# MEC1322 register map
Vendor: Microchip Technology Inc.; Series: ARMCM4F; File version: 1.0
CPU: CM4 r1p0, little endian, MPU, FPU, 3 interrupt priority bits
Registers are 32-bit, read-write, reset 0x0 unless marked. A register's access mark holds for its fields unless they carry their own. Offsets are from the block's base; [hi:lo] are bit positions; lines under a group give offsets from that group; {n}, {i} and the like mark numbered series.

## PECI — The MEC1322 includes a PECI Interface to allow the EC to retrieve temperature readings from PECI-compliant devices.
Base 0x40006400
0x00 WRITE_DATA 8-bit — The Write Data Register provides access to a 32-byte Transmit FIFO.
0x04 READ_DATA 8-bit — The Read Data Register provides access to a 32-byte Receive FIFO.
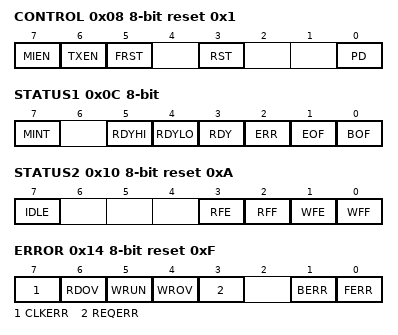
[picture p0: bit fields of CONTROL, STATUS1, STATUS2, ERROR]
0x08 CONTROL 8-bit reset 0x1
  [7] MIEN — MIEN is the Master Interrupt Enable
  [6] TXEN — TXEN is the Transmit Enable bit.
  [5] FRST — FRST is the FIFO Reset bit.
  [3] RST — RST indicates that the PECI Core should be reset.
  [0] PD — PD (Power Down) along with RST controls the Power Management Interface
0x0C STATUS1 8-bit — Status Register 1
  [7] MINT read — MINT is the Master Interrupt Status bit and is asserted when any interrupt status bit in the Interrupt Interface is asserted.
  [5] RDYHI — RDYHI is asserted '1' on the rising edge of the READY signal function (R/WC)
  [4] RDYLO — RDYLO is asserted '1' on the falling edge of the READY signal function (R/WC)
  [3] RDY read — RDY represents the state of the READY signal function
  [2] ERR read — ERR Indicates that an error for the current transaction has been detected.
  [1] EOF — EOF (End of Frame) is asserted following Message Stop (tSTOP). (R/WC)
  [0] BOF — BOF (Beginning of Frame) is asserted when the PECI Core begins Address Timing Negotiation. (R/WC)
0x10 STATUS2 8-bit read reset 0xA — Status Register 2
  [7] IDLE — The IDLE status bit indicates when the SST/PECI bus is idle and a new transaction may begin.
  [3] RFE — RFE indicates that the Read Data Register FIFO is empty. RFE does not generate an interrupt.
  [2] RFF — RFF indicates that the Read Data Register FIFO is full.
  [1] WFE — WFE indicates that the Write Data Register FIFO is empty.
  [0] WFF — WFF indicates that the Write Data Register FIFO is full. WFF does not generate an interrupt.
0x14 ERROR 8-bit reset 0xF
  [7] CLKERR — CLKERR indicates that the READY signal function in the Hardware Interface was de-asserted in the middle of a transaction (R/WC)
  [6] RDOV — RDOV (Read Overrun). RDOV indicates that the internal read buffer has overflowed (R/WC)
  [5] WRUN — WRUN (Write Underrun). (R/WC)
  [4] WROV — WROV (Write Overrun). (R/WC)
  [3] REQERR — REQERR is asserted if PEC_AVAILABLE (READY) input is not asserted when the counts down to zero as shown in. When asserted, REQERR can generate interrupt. (R/WC)
  [1] BERR — BERR (Bus Error). Bus contention has been detected. BERR is asserted when the PECI Module reads a value that is different from what it has driven (R/WC)
  [0] FERR — FERR (Frame Check Sequence Error). (R/WC)
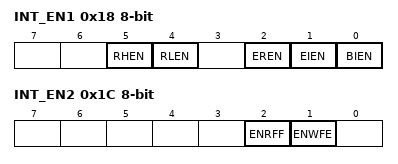
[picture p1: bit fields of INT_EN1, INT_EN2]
0x18 INT_EN1 8-bit — Interrupt Enable 1 Register
  [5] RHEN — When the RHEN bit is asserted '1' the RDYHI interrupt is enabled.
  [4] RLEN — When the RLEN bit is asserted '1' the RDYLO interrupt is enabled.
  [2] EREN — When the EREN bit is asserted '1' the ERR interrupt is enabled.
  [1] EIEN — When the EIEN bit is asserted '1' the EOF interrupt is enabled.
  [0] BIEN — When the BIEN bit is asserted '1' the BOF interrupt is enabled.
0x1C INT_EN2 8-bit — Interrupt Enable 2 Register
  [2] ENRFF — When the ENRFF bit is asserted '1' the RFF interrupt is enabled.
  [1] ENWFE — When the ENWFE bit is asserted '1' the WFE interrupt is enabled.
0x20 OBT1 8-bit reset 0x16 — Optimal Bit Time Register (Low Byte)
0x24 OBT2 8-bit — Optimal Bit Time Register (High Byte)
0x40 ID reset 0xF (reset mask 0xFFFF) — Block ID Register
0x44 REV reset 0xF (reset mask 0xFFFF) — Revision Register

## TACH — This block monitors TACH output signals (or locked rotor signals) from various types of fans, and determines their speed.
Base 0x40006000
{0x0+0x10*i} CH[{i}] (i=0..1) group — Channel implemented will have these registers to determine that channel's operation.
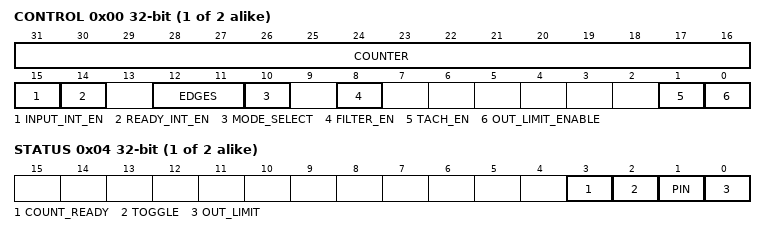
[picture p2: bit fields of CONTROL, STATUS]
  0x00 CONTROL — TACHx Control Register
    [31:16] COUNTER read — This 16-bit field contains the latched value of the internal Tach pulse counter, which may be configured by the Tach Reading Mode Select field to operate as a free-running counter or to be gated by the Tach input signal.
    [15] INPUT_INT_EN — TACH_INPUT_INT_EN 1=Enable Tach Input toggle interrupt from Tach block, 0=Disable Tach Input toggle interrupt from Tach block
    [14] READY_INT_EN — COUNT_READY_INT_EN 1=Enable Count Ready interrupt from Tach block, 0=Disable Count Ready interrupt from Tach block
    [12:11] EDGES — TACH_EDGES A Tach signal is a square wave with a 50% duty cycle. Typically, two Tach periods represents one revolution of the fan. A Tach period consists of three Tach edges. This programmed value represents the number of Tach edges that will be used to determine the interval for which the number of 100kHz_Clk pulses will be counted. 11b=9 Tach edges (4 Tach periods). 10b=5 Tach edges (2 Tach periods). 01b=3 Tach edges (1 Tach period). 00b=2 Tach edges (1/2 Tach period)
    [10] MODE_SELECT — TACH_READING_MODE_SELECT. 1=Counter is incremented on the rising edge of the 100kHz_Clk input. The counter is latched into the TACHX_COUNTER field and reset when the programmed number of edges is detected. 0=Counter is incremented when Tach Input transitions from low-tohigh state (default)
    [8] FILTER_EN — FILTER_ENABLE This filter is used to remove high frequency glitches from Tach Input. When this filter is enabled, Tach input pulses less than two 100kHz_- Clk periods wide get filtered. 1= Filter enabled. 0= Filter disabled (default). It is recommended that the Tach input filter always be enabled.
    [1] TACH_EN — TACH_ENABLE 1= TACH Monitoring enabled, clocks enabled. 0= TACH Idle, clocks gated
    [0] OUT_LIMIT_ENABLE — TACH_OUT_OF_LIMIT_ENABLE This bit is used to enable the TACH_OUT_OF_LIMIT_STATUS bit in the TACHx Status Register to generate an interrupt event. 1=Enable interrupt output from Tach block. 0=Disable interrupt output from Tach block (default)
  0x04 STATUS — TACHx Status Register
    [3] COUNT_READY — COUNT_READY_STATUS 1=Reading ready, 0=Reading not ready
    [2] TOGGLE — TOGGLE_STATUS 1=Tach Input changed state (this bit is set on a low-to-high or high-tolow transition), 0=Tach stable (R/WC)
    [1] PIN read — TACH_PIN_STATUS 1= Tach Input is high, 0= Tach Input is low
    [0] OUT_LIMIT — TACH_OUT_OF_LIMIT_STATUS 1=Tach is outside of limits, 0=Tach is within limits (R/WC)
  0x08 HIGH_LIMIT 16-bit reset 0xFFFF — This value is compared with the value in the TACHX_COUNTER field. If the value in the counter is greater than the value programmed in this register, the TACH_OUT_OF_LIMIT_STATUS bit will be set.
  0x0C LOW_LIMIT 16-bit — This value is compared with the value in the TACHX_COUNTER field of the TACHx Control Register. If the value in the counter is less than the value programmed in this register, the TACH_OUT_OF_LIMIT_STATUS bit will be set.
